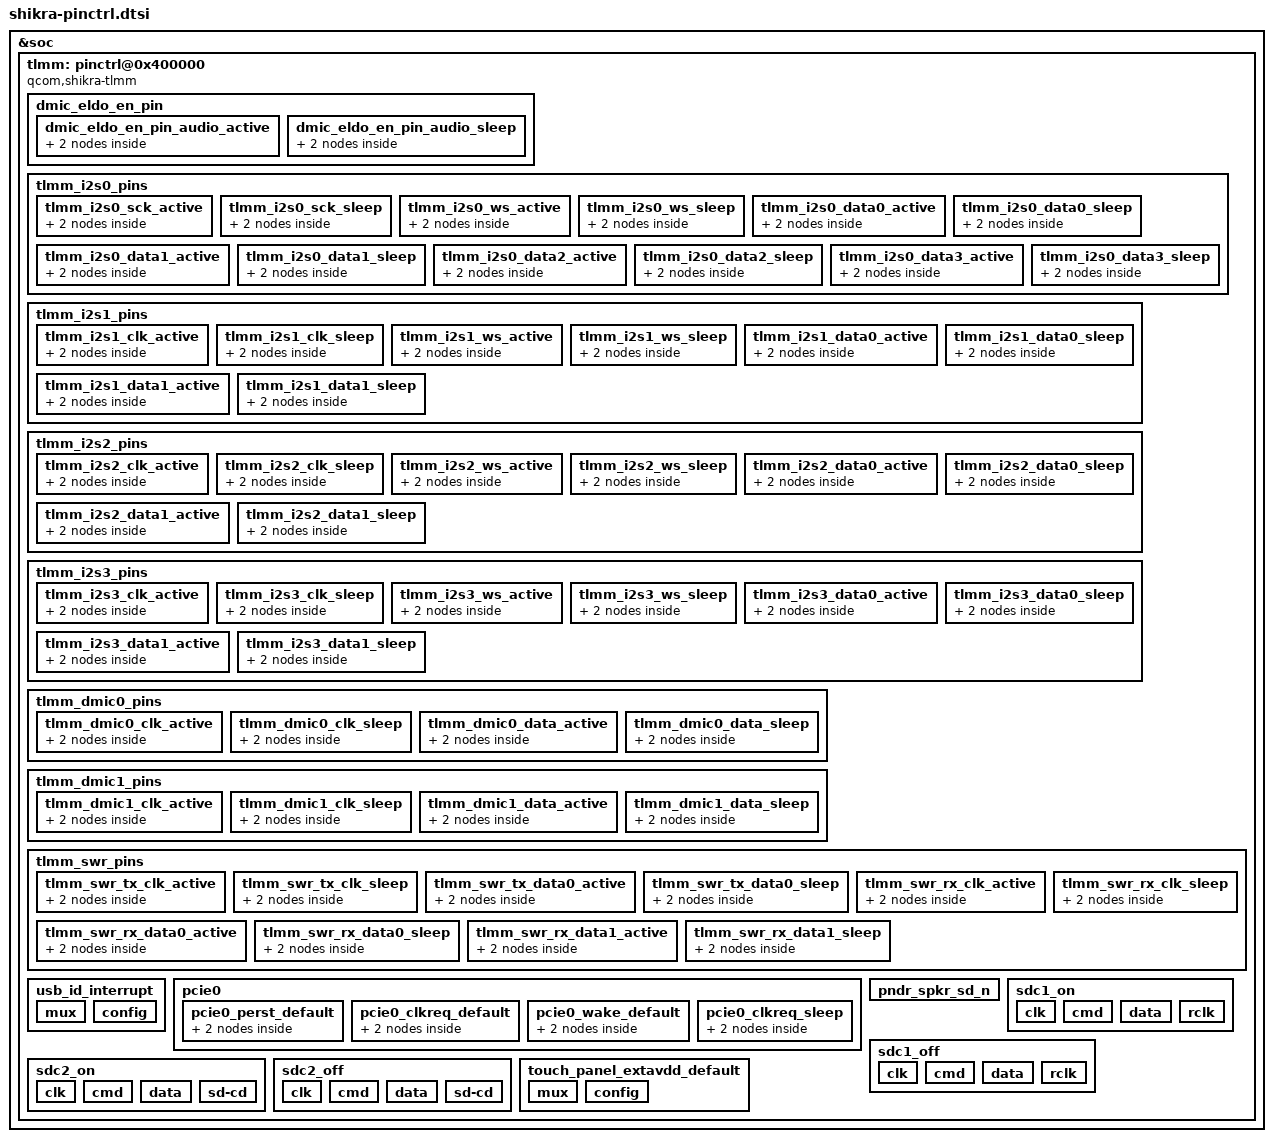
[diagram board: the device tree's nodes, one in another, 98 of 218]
// SPDX-License-Identifier: BSD-3-Clause
/*
 *Copyright (c) Qualcomm Technologies, Inc. and/or its subsidiaries.
 */

&soc {

	tlmm: pinctrl@0x400000 {
		compatible = "qcom,shikra-tlmm";
		reg = <0x400000 0x800000>;
		interrupts = <GIC_SPI 227 IRQ_TYPE_LEVEL_HIGH>;
		gpio-controller;
		#gpio-cells = <2>;
		interrupt-controller;
		#interrupt-cells = <2>;
		wakeup-parent = <&mpm>;
		qcom,gpios-reserved = <115 116 6 7 8 9 14 15 16 17 138>;

		dmic_eldo_en_pin: dmic_eldo_en_pin {
			dmic_eldo_en_pin_audio_active: dmic_eldo_en_pin_audio_active {
				mux {
					pins = "gpio71";
					function = "gpio";
				};

				config {
					pins = "gpio71";
					drive-strength = <8>;   /* 8 mA */
					bias-disable;
					output-high;
				};
			};

			dmic_eldo_en_pin_audio_sleep: dmic_eldo_en_pin_audio_sleep {
				mux {
					pins = "gpio71";
					function = "gpio";
				};

				config {
					pins = "gpio71";
					drive-strength = <2>;   /* 2 mA */
					bias-disable;
					output-low;
				};
			};
		};

		tlmm_i2s0_pins: tlmm_i2s0_pins {
			tlmm_i2s0_sck_active: tlmm_i2s0_sck_active {
				mux {
					pins = "gpio105";
					function = "i2s0_clk";
				};

				config {
					pins = "gpio105";
					drive-strength = <8>;   /* 8 mA */
					bias-disable;           /* NO PULL */
					output-high;
				};
			};

			tlmm_i2s0_sck_sleep: tlmm_i2s0_sck_sleep {
				mux {
					pins = "gpio105";
					function = "gpio";
				};

				config {
					pins = "gpio105";
					drive-strength = <2>;   /* 2 mA */
					bias-pull-down;         /* PULL DOWN */
					input-enable;
				};
			};

			tlmm_i2s0_ws_active: tlmm_i2s0_ws_active {
				mux {
					pins = "gpio106";
					function = "i2s0_ws";
				};

				config {
					pins = "gpio106";
					drive-strength = <8>;   /* 8 mA */
					bias-disable;           /* NO PULL */
					output-high;
				};
			};

			tlmm_i2s0_ws_sleep: tlmm_i2s0_ws_sleep {
				mux {
					pins = "gpio106";
					function = "gpio";
				};

				config {
					pins = "gpio106";
					drive-strength = <2>;   /* 2 mA */
					bias-pull-down;         /* PULL DOWN */
					input-enable;
				};
			};

			tlmm_i2s0_data0_active: tlmm_i2s0_data0_active {
				mux {
					pins = "gpio107";
					function = "i2s0_data0";
				};

				config {
					pins = "gpio107";
					drive-strength = <8>;   /* 8 mA */
					bias-disable;           /* NO PULL */
					output-high;
				};
			};

			tlmm_i2s0_data0_sleep: tlmm_i2s0_data0_sleep {
				mux {
					pins = "gpio107";
					function = "gpio";
				};

				config {
					pins = "gpio107";
					drive-strength = <2>;   /* 2 mA */
					bias-pull-down;         /* PULL DOWN */
					input-enable;
				};
			};

			tlmm_i2s0_data1_active: tlmm_i2s0_data1_active {
				mux {
					pins = "gpio108";
					function = "i2s0_data1";
				};

				config {
					pins = "gpio108";
					drive-strength = <8>;   /* 8 mA */
					bias-disable;           /* NO PULL */
					output-high;
				};
			};

			tlmm_i2s0_data1_sleep: tlmm_i2s0_data1_sleep {
				mux {
					pins = "gpio108";
					function = "gpio";
				};

				config {
					pins = "gpio108";
					drive-strength = <2>;   /* 2 mA */
					bias-pull-down;         /* PULL DOWN */
					input-enable;
				};
			};

			tlmm_i2s0_data2_active: tlmm_i2s0_data2_active {
				mux {
					pins = "gpio109";
					function = "i2s0_data2";
				};

				config {
					pins = "gpio109";
					drive-strength = <8>;   /* 8 mA */
					bias-disable;           /* NO PULL */
					output-high;
				};
			};

			tlmm_i2s0_data2_sleep: tlmm_i2s0_data2_sleep {
				mux {
					pins = "gpio109";
					function = "gpio";
				};

				config {
					pins = "gpio109";
					drive-strength = <2>;   /* 2 mA */
					bias-pull-down;         /* PULL DOWN */
					input-enable;
				};
			};

			tlmm_i2s0_data3_active: tlmm_i2s0_data3_active {
				mux {
					pins = "gpio110";
					function = "i2s0_data3";
				};

				config {
					pins = "gpio110";
					drive-strength = <8>;   /* 8 mA */
					bias-disable;           /* NO PULL */
					output-high;
				};
			};

			tlmm_i2s0_data3_sleep: tlmm_i2s0_data3_sleep {
				mux {
					pins = "gpio110";
					function = "gpio";
				};

				config {
					pins = "gpio110";
					drive-strength = <2>;   /* 2 mA */
					bias-pull-down;         /* PULL DOWN */
					input-enable;
				};
			};
		};

		tlmm_i2s1_pins: tlmm_i2s1_pins {
			tlmm_i2s1_clk_active: tlmm_i2s1_clk_active {
				mux {
					pins = "gpio96";
					function = "i2s1_clk";
				};

				config {
					pins = "gpio96";
					drive-strength = <8>;   /* 8 mA */
					bias-disable;           /* NO PULL */
					output-high;
				};
			};

			tlmm_i2s1_clk_sleep: tlmm_i2s1_clk_sleep {
				mux {
					pins = "gpio96";
					function = "gpio";
				};

				config {
					pins = "gpio96";
					drive-strength = <2>;   /* 2 mA */
					bias-pull-down;         /* PULL DOWN */
					input-enable;
				};
			};

			tlmm_i2s1_ws_active: tlmm_i2s1_ws_active {
				mux {
					pins = "gpio97";
					function = "i2s1_ws";
				};

				config {
					pins = "gpio97";
					drive-strength = <8>;   /* 8 mA */
					bias-disable;           /* NO PULL */
					output-high;
				};
			};

			tlmm_i2s1_ws_sleep: tlmm_i2s1_ws_sleep {
				mux {
					pins = "gpio97";
					function = "gpio";
				};

				config {
					pins = "gpio97";
					drive-strength = <2>;   /* 2 mA */
					bias-pull-down;         /* PULL DOWN */
					input-enable;
				};
			};

			tlmm_i2s1_data0_active: tlmm_i2s1_data0_active {
				mux {
					pins = "gpio98";
					function = "i2s1_data0";
				};

				config {
					pins = "gpio98";
					drive-strength = <8>;   /* 8 mA */
					bias-disable;           /* NO PULL */
					output-high;
				};
			};

			tlmm_i2s1_data0_sleep: tlmm_i2s1_data0_sleep {
				mux {
					pins = "gpio98";
					function = "gpio";
				};

				config {
					pins = "gpio98";
					drive-strength = <2>;   /* 2 mA */
					bias-pull-down;         /* PULL DOWN */
					input-enable;
				};
			};

			tlmm_i2s1_data1_active: tlmm_i2s1_data1_active {
				mux {
					pins = "gpio99";
					function = "i2s1_data1";
				};

				config {
					pins = "gpio99";
					drive-strength = <8>;   /* 8 mA */
					bias-disable;           /* NO PULL */
					output-high;
				};
			};

			tlmm_i2s1_data1_sleep: tlmm_i2s1_data1_sleep {
				mux {
					pins = "gpio99";
					function = "gpio";
				};

				config {
					pins = "gpio99";
					drive-strength = <2>;   /* 2 mA */
					bias-pull-down;         /* PULL DOWN */
					input-enable;
				};
			};
		};

		tlmm_i2s2_pins: tlmm_i2s2_pins {
			tlmm_i2s2_clk_active: tlmm_i2s2_clk_active {
				mux {
					pins = "gpio100";
					function = "i2s2_clk";
				};

				config {
					pins = "gpio100";
					drive-strength = <8>;   /* 8 mA */
					bias-disable;           /* NO PULL */
					output-high;
				};
			};

			tlmm_i2s2_clk_sleep: tlmm_i2s2_clk_sleep {
				mux {
					pins = "gpio100";
					function = "gpio";
				};

				config {
					pins = "gpio100";
					drive-strength = <2>;   /* 2 mA */
					bias-pull-down;         /* PULL DOWN */
					input-enable;
				};
			};

			tlmm_i2s2_ws_active: tlmm_i2s2_ws_active {
				mux {
					pins = "gpio101";
					function = "i2s2_ws";
				};

				config {
					pins = "gpio101";
					drive-strength = <8>;   /* 8 mA */
					bias-disable;           /* NO PULL */
					output-high;
				};
			};

			tlmm_i2s2_ws_sleep: tlmm_i2s2_ws_sleep {
				mux {
					pins = "gpio101";
					function = "gpio";
				};

				config {
					pins = "gpio101";
					drive-strength = <2>;   /* 2 mA */
					bias-pull-down;         /* PULL DOWN */
					input-enable;
				};
			};


			tlmm_i2s2_data0_active: tlmm_i2s2_data0_active {
				mux {
					pins = "gpio102";
					function = "i2s2_data0";
				};

				config {
					pins = "gpio102";
					drive-strength = <8>;   /* 8 mA */
					bias-disable;           /* NO PULL */
					output-high;
				};
			};

			tlmm_i2s2_data0_sleep: tlmm_i2s2_data0_sleep {
				mux {
					pins = "gpio102";
					function = "gpio";
				};

				config {
					pins = "gpio102";
					drive-strength = <2>;   /* 2 mA */
					bias-pull-down;         /* PULL DOWN */
					input-enable;
				};
			};


			tlmm_i2s2_data1_active: tlmm_i2s2_data1_active {
				mux {
					pins = "gpio103";
					function = "i2s2_data1";
				};

				config {
					pins = "gpio103";
					drive-strength = <8>;   /* 8 mA */
					bias-disable;           /* NO PULL */
					output-high;
				};
			};

			tlmm_i2s2_data1_sleep: tlmm_i2s2_data1_sleep {
				mux {
					pins = "gpio103";
					function = "gpio";
				};

				config {
					pins = "gpio103";
					drive-strength = <2>;   /* 2 mA */
					bias-pull-down;         /* PULL DOWN */
					input-enable;
				};
			};
		};

		tlmm_i2s3_pins: tlmm_i2s3_pins {
			tlmm_i2s3_clk_active: tlmm_i2s3_clk_active {
				mux {
					pins = "gpio111";
					function = "i2s3_clk";
				};

				config {
					pins = "gpio111";
					drive-strength = <8>;   /* 8 mA */
					bias-disable;           /* NO PULL */
					output-high;
				};
			};

			tlmm_i2s3_clk_sleep: tlmm_i2s3_clk_sleep {
				mux {
					pins = "gpio111";
					function = "gpio";
				};

				config {
					pins = "gpio111";
					drive-strength = <2>;   /* 2 mA */
					bias-pull-down;         /* PULL DOWN */
					input-enable;
				};
			};

			tlmm_i2s3_ws_active: tlmm_i2s3_ws_active {
				mux {
					pins = "gpio112";
					function = "i2s3_ws";
				};

				config {
					pins = "gpio112";
					drive-strength = <8>;   /* 8 mA */
					bias-disable;           /* NO PULL */
					output-high;
				};
			};

			tlmm_i2s3_ws_sleep: tlmm_i2s3_ws_sleep {
				mux {
					pins = "gpio112";
					function = "gpio";
				};

				config {
					pins = "gpio112";
					drive-strength = <2>;   /* 2 mA */
					bias-pull-down;         /* PULL DOWN */
					input-enable;
				};
			};

			tlmm_i2s3_data0_active: tlmm_i2s3_data0_active {
				mux {
					pins = "gpio113";
					function = "i2s3_data0";
				};

				config {
					pins = "gpio113";
					drive-strength = <8>;   /* 8 mA */
					bias-disable;           /* NO PULL */
					output-high;
				};
			};

			tlmm_i2s3_data0_sleep: tlmm_i2s3_data0_sleep {
				mux {
					pins = "gpio113";
					function = "gpio";
				};

				config {
					pins = "gpio113";
					drive-strength = <2>;   /* 2 mA */
					bias-pull-down;         /* PULL DOWN */
					input-enable;
				};
			};

			tlmm_i2s3_data1_active: tlmm_i2s3_data1_active {
				mux {
					pins = "gpio114";
					function = "i2s3_data1";
				};

				config {
					pins = "gpio114";
					drive-strength = <8>;   /* 8 mA */
					bias-disable;           /* NO PULL */
					output-high;
				};
			};

			tlmm_i2s3_data1_sleep: tlmm_i2s3_data1_sleep {
				mux {
					pins = "gpio114";
					function = "gpio";
				};

				config {
					pins = "gpio114";
					drive-strength = <2>;   /* 2 mA */
					bias-pull-down;         /* PULL DOWN */
					input-enable;
				};
			};
		};

		tlmm_dmic0_pins: tlmm_dmic0_pins {
			tlmm_dmic0_clk_active: tlmm_dmic0_clk_active {
				mux {
					pins = "gpio96";
					function = "dmic0_clk";
				};

				config {
					pins = "gpio96";
					drive-strength = <8>;
					output-high;
				};
			};

			tlmm_dmic0_clk_sleep: tlmm_dmic0_clk_sleep {
				mux {
					pins = "gpio96";
					function = "gpio";
				};

				config {
					pins = "gpio96";
					drive-strength = <2>;
					bias-disable;
					output-low;
				};
			};

			tlmm_dmic0_data_active: tlmm_dmic0_data_active {
				mux {
					pins = "gpio97";
					function = "dmic0_data";
				};

				config {
					pins ="gpio97";
					drive-strength = <8>;
					input-enable;
				};
			};

			tlmm_dmic0_data_sleep: tlmm_dmic0_data_sleep {
				mux {
					pins = "gpio97";
					function = "gpio";
				};

				config {
					pins = "gpio97";
					drive-strength = <2>;
					pull-down;
					input-enable;
				};
			};
		};

		tlmm_dmic1_pins: tlmm_dmic1_pins {
			tlmm_dmic1_clk_active: tlmm_dmic1_clk_active {
				mux {
					pins = "gpio98";
					function = "dmic1_clk";
				};

				config {
					pins = "gpio98";
					drive-strength = <8>;
					output-high;
				};
			};

			tlmm_dmic1_clk_sleep: tlmm_dmic1_clk_sleep {
				mux {
					pins = "gpio98";
					function = "gpio";
				};

				config {
					pins = "gpio98";
					drive-strength = <2>;
					bias-disable;
					output-low;
				};
			};

			tlmm_dmic1_data_active: tlmm_dmic1_data_active {
				mux {
					pins = "gpio99";
					function = "dmic1_data";
				};

				config {
					pins ="gpio99";
					drive-strength = <8>;
					input-enable;
				};
			};

			tlmm_dmic1_data_sleep: tlmm_dmic1_data_sleep {
				mux {
					pins = "gpio99";
					function = "gpio";
				};

				config {
					pins = "gpio99";
					drive-strength = <2>;
					pull-down;
					input-enable;
				};
			};
		};

		tlmm_swr_pins: tlmm_swr_pins {
			tlmm_swr_tx_clk_active: tlmm_swr_tx_clk_active {
				mux {
					pins = "gpio105";
					function = "swr0_tx_clk";
				};

				config {
					pins = "gpio105";
					drive-strength = <4>;
					bias-disable;
				};
			};

			tlmm_swr_tx_clk_sleep: tlmm_swr_tx_clk_sleep {
				mux {
					pins = "gpio105";
					function = "gpio";
					input-enable;
					bias-pull-down;
				};

				config {
					pins = "gpio105";
					drive-strength = <2>;
				};
			};

			tlmm_swr_tx_data0_active: tlmm_swr_tx_data0_active {
				mux {
					pins = "gpio106";
					function = "swr0_tx_data0";
				};

				config {
					pins = "gpio106";
					drive-strength = <4>;
					bias-bus-hold;
				};
			};

			tlmm_swr_tx_data0_sleep: tlmm_swr_tx_data0_sleep {
				mux {
					pins = "gpio106";
					function = "gpio";
				};

				config {
					pins = "gpio106";
					drive-strength = <2>;
					input-enable;
					bias-bus-hold;
				};
			};


			tlmm_swr_rx_clk_active: tlmm_swr_rx_clk_active {
				mux {
					pins = "gpio107";
					function = "swr0_rx_clk";
				};

				config {
					pins = "gpio107";
					drive-strength = <2>;
					bias-disable;
				};
			};

			tlmm_swr_rx_clk_sleep: tlmm_swr_rx_clk_sleep {
				mux {
					pins = "gpio107";
					function = "gpio";
				};

				config {
					pins = "gpio107";
					drive-strength = <2>;
					input-enable;
					bias-pull-down;
				};
			};

			tlmm_swr_rx_data0_active: tlmm_swr_rx_data0_active {
				mux {
					pins = "gpio108";
					function = "swr0_rx_data0";
				};

				config {
					pins = "gpio108";
					drive-strength = <2>;
					bias-bus-hold;
				};
			};

			tlmm_swr_rx_data0_sleep: tlmm_swr_rx_data0_sleep {
				mux {
					pins = "gpio108";
					function = "gpio";
				};

				config {
					pins = "gpio108";
					drive-strength = <2>;
					input-enable;
					bias-pull-down;
				};
			};


			tlmm_swr_rx_data1_active: tlmm_swr_rx_data1_active {
				mux {
					pins = "gpio109";
					function = "swr0_rx_data1";
				};

				config {
					pins = "gpio109";
					drive-strength = <2>;
					bias-bus-hold;
				};
			};

			tlmm_swr_rx_data1_sleep: tlmm_swr_rx_data1_sleep {
				mux {
					pins = "gpio109";
					function = "gpio";
				};

				config {
					pins = "gpio109";
					drive-strength = <2>;
					input-enable;
					bias-pull-down;
				};
			};
		};

		usb_id_interrupt: usb_id_interrupt {
			mux {
				pins = "gpio90";
				function = "gpio";
			};

			config {
				pins = "gpio90";
				bias-pull-up;
				input-enable;
			};
		};

		pcie0 {
			pcie0_perst_default: pcie0_perst_default {
				mux {
					pins = "gpio118";
					function = "gpio";
				};

				config {
					pins = "gpio118";
					drive-strength = <2>;
					bias-pull-down;
				};
			};

			pcie0_clkreq_default: pcie0_clkreq_default {
				mux {
					pins = "gpio117";
					function = "pcie0_clk_req_n";
				};

				config {
					pins = "gpio117";
					drive-strength = <2>;
					bias-pull-up;
				};
			};

			pcie0_wake_default: pcie0_wake_default {
				mux {
					pins = "gpio119";
					function = "gpio";
				};

				config {
					pins = "gpio119";
					drive-strength = <2>;
					bias-pull-up;
				};
			};

			pcie0_clkreq_sleep: pcie0_clkreq_sleep {
				mux {
					pins = "gpio117";
					function = "gpio";
				};

				config {
					pins = "gpio117";
					drive-strength = <2>;
					bias-pull-up;
				};
			};
		};

		pndr_spkr_sd_n: pndr_spkr_sd_n {
			pins = "gpio2";
			function = "gpio";
			input-disable;
			output-enable;
		};

		sdc1_on: sdc1_on {
			clk {
				pins = "sdc1_clk";
				bias-disable;
				drive-strength = <6>;
			};


			cmd {
				pins = "sdc1_cmd";
				bias-pull-up;
				drive-strength = <6>;
			};


			data {
				pins = "sdc1_data";
				bias-pull-up;
				drive-strength = <6>;
			};

			rclk {
				pins = "sdc1_rclk";
				bias-pull-down;
				drive-strength = <4>;
			};
		};

		sdc1_off: sdc1_off {
			clk {
				pins = "sdc1_clk";
				drive-strength = <2>;
				bias-bus-hold;
			};

			cmd {
				pins = "sdc1_cmd";
				drive-strength = <2>;
				bias-bus-hold;
			};

			data {
				pins = "sdc1_data";
				drive-strength = <2>;
				bias-bus-hold;
			};

			rclk {
				pins = "sdc1_rclk";
				drive-strength = <2>;
				bias-bus-hold;
			};
		};

		sdc2_on: sdc2_on {
			clk {
				pins = "sdc2_clk";
				bias-disable;
				drive-strength = <14>;
			};

			cmd {
				pins = "sdc2_cmd";
				bias-pull-up;
				drive-strength = <14>;
			};

			data {
				pins = "sdc2_data";
				bias-pull-up;
				drive-strength = <14>;
			};

			sd-cd {
				pins = "gpio89";
				bias-pull-up;
				drive-strength = <2>;
			};
		};

		sdc2_off: sdc2_off {
			clk {
				pins = "sdc2_clk";
				bias-disable;
				drive-strength = <2>;
			};

			cmd {
				pins = "sdc2_cmd";
				bias-pull-up;
				drive-strength = <2>;
			};

			data {
				pins = "sdc2_data";
				bias-pull-up;
				drive-strength = <2>;
			};

			sd-cd {
				pins = "gpio89";
				bias-pull-up;
				drive-strength = <2>;
			};
		};

		touch_panel_extavdd_default: touch_panel_extavdd_default {
			mux {
				pins = "gpio63";
				function = "gpio";
			};

			config {
				pins = "gpio63";
				drive-strength = <8>;
				bias-disable = <0>;
				output-high;
			};
		};
	};
};
